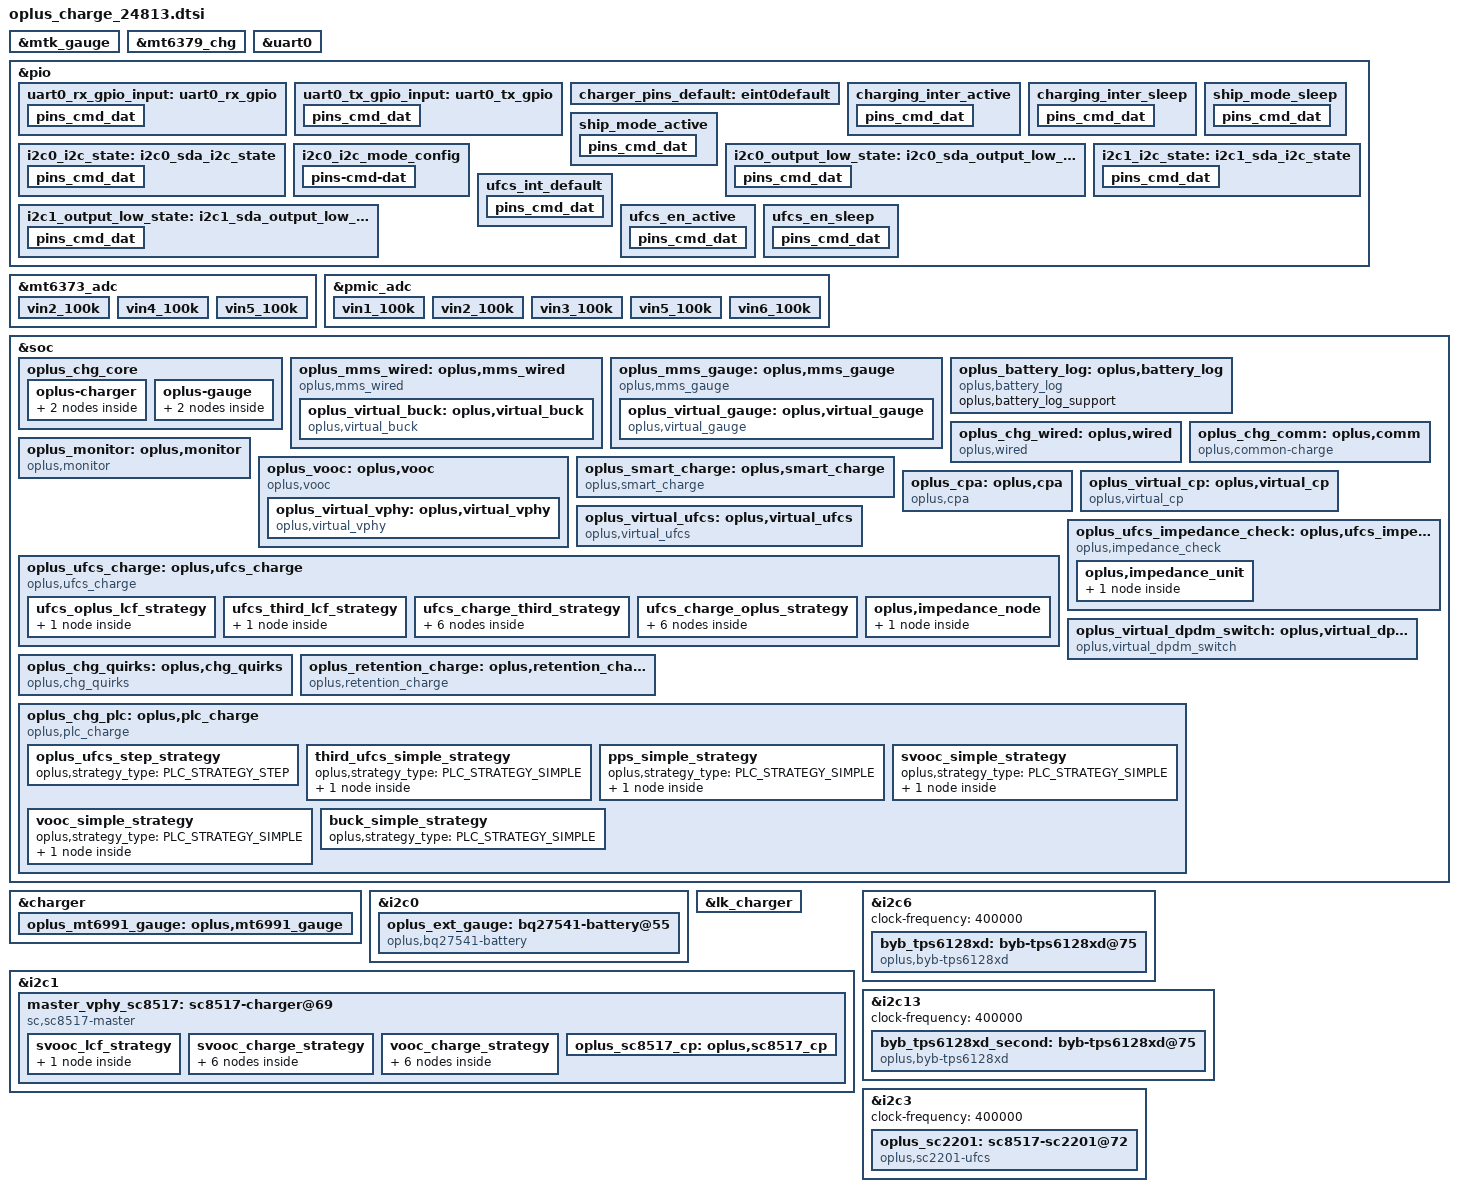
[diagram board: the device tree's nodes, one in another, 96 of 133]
// SPDX-License-Identifier: GPL-2.0-only
/*
* Copyright (C) 2024 Oplus. All rights reserved.
*/
#include <dt-bindings/iio/mt635x-auxadc.h>
#include <dt-bindings/pinctrl/mt6991-pinfunc.h>
#include <dt-bindings/pinctrl/mt65xx.h>
#include "oplus_chg.h"

/* charge start */
&mtk_gauge {
	disable-mtkbattery = <(1)>;
	charger = <&mt6379_chg>;
};

&mt6379_chg {
	chg-tmr = <15>;
};

&uart0 {
	pinctrl-names = "uart0_rx_gpio", "uart0_tx_gpio";
	pinctrl-0 = <&uart0_rx_gpio_input>;
	pinctrl-1 = <&uart0_tx_gpio_input>;
	status = "okay";

	txpin = <160>;
	rxpin = <161>;
};

&pio {
	uart0_rx_gpio_input: uart0_rx_gpio {
		pins_cmd_dat {
			pinmux = <PINMUX_GPIO161__FUNC_GPIO161>;
			input-enable;
			bias-disable;
		};
	};

	uart0_tx_gpio_input: uart0_tx_gpio {
		pins_cmd_dat {
			pinmux = <PINMUX_GPIO160__FUNC_GPIO160>;
			input-enable;
			bias-disable;
		};
	};
};

/* mt6373_adc is defined in mt6373.dtsi */
&mt6373_adc {
	vin2_100k {
		channel = <AUXADC_VIN2>;
		pures = <ADC_PURES_100K>;
	};
	vin4_100k {
		channel = <AUXADC_VIN4>;
		pures = <ADC_PURES_100K>;
	};
	vin5_100k {
		channel = <AUXADC_VIN5>;
		pures = <ADC_PURES_100K>;
	};
};

/* pmic_adc is defined in mt6363.dtsi */
&pmic_adc {
	vin1_100k {
		channel = <AUXADC_VIN1>;
		pures = <ADC_PURES_100K>;
	};
	vin2_100k {
		channel = <AUXADC_VIN2>;
		pures = <ADC_PURES_100K>;
	};
	vin3_100k {
		channel = <AUXADC_VIN3>;
		pures = <ADC_PURES_100K>;
	};
	vin5_100k {
		channel = <AUXADC_VIN5>;
		pures = <ADC_PURES_100K>;
	};
	vin6_100k {
		channel = <AUXADC_VIN6>;
		pures = <ADC_PURES_100K>;
	};
};

&pio {
	charger_pins_default: eint0default {
	};

	charging_inter_active: charging_inter_active {
		pins_cmd_dat {
			pinmux = <PINMUX_GPIO216__FUNC_GPIO216>;
			input-enable;
			bias-pull-up;
		};
	};

	charging_inter_sleep: charging_inter_sleep {
		pins_cmd_dat {
			pinmux = <PINMUX_GPIO216__FUNC_GPIO216>;
			input-enable;
			bias-pull-up;
		};
	};

	ship_mode_sleep: ship_mode_sleep {
		pins_cmd_dat {
			pinmux = <PINMUX_GPIO93__FUNC_GPIO93>;
			output-low;
		};
	};

	ship_mode_active: ship_mode_active {
		pins_cmd_dat {
			pinmux = <PINMUX_GPIO93__FUNC_GPIO93>;
			output-high;
		};
	};
};

&soc {
	oplus_chg_core {
		oplus,chg_framework_v2;
		oplus,smart_charging_screenoff;
		oplus,chg_spec_version = <OPLUS_CHG_SPEC_VER_V3P7>;

		oplus-charger {
			mtk_6991_groups: oplus,mtk_6991-groups {
				functions = <
					OPLUS_IC_FUNC_INIT
					OPLUS_IC_FUNC_EXIT
					OPLUS_IC_FUNC_REG_DUMP
					OPLUS_IC_FUNC_SMT_TEST
					OPLUS_IC_FUNC_BUCK_INPUT_PRESENT
					OPLUS_IC_FUNC_BUCK_INPUT_SUSPEND
					OPLUS_IC_FUNC_BUCK_INPUT_IS_SUSPEND
					OPLUS_IC_FUNC_BUCK_OUTPUT_SUSPEND
					OPLUS_IC_FUNC_BUCK_OUTPUT_IS_SUSPEND
					OPLUS_IC_FUNC_BUCK_SET_ICL
					OPLUS_IC_FUNC_BUCK_GET_ICL
					OPLUS_IC_FUNC_BUCK_SET_FCC
					OPLUS_IC_FUNC_BUCK_SET_FV
					OPLUS_IC_FUNC_BUCK_SET_ITERM
					OPLUS_IC_FUNC_BUCK_GET_INPUT_CURR
					OPLUS_IC_FUNC_BUCK_GET_INPUT_VOL
					OPLUS_IC_FUNC_OTG_BOOST_ENABLE
					OPLUS_IC_FUNC_BUCK_GET_CC_ORIENTATION
					OPLUS_IC_FUNC_BUCK_GET_CHARGER_TYPE
					OPLUS_IC_FUNC_BUCK_RERUN_BC12
					OPLUS_IC_FUNC_BUCK_QC_DETECT_ENABLE
					OPLUS_IC_FUNC_BUCK_SET_QC_CONFIG
					OPLUS_IC_FUNC_BUCK_SET_PD_CONFIG
					OPLUS_IC_FUNC_GET_SHUTDOWN_SOC
					OPLUS_IC_FUNC_BACKUP_SOC
					OPLUS_IC_FUNC_GET_TYPEC_MODE
					OPLUS_IC_FUNC_SET_TYPEC_MODE
					OPLUS_IC_FUNC_GET_TYPEC_ROLE
					OPLUS_IC_FUNC_GET_OTG_ENABLE
					OPLUS_IC_FUNC_BUCK_GET_HW_DETECT
					OPLUS_IC_FUNC_SET_USB_DISCHG_ENABLE
					OPLUS_IC_FUNC_GET_USB_DISCHG_STATUS
					OPLUS_IC_FUNC_IS_OPLUS_SVID
					OPLUS_IC_FUNC_BUCK_GET_USB_BTB_TEMP
					OPLUS_IC_FUNC_BUCK_GET_BATT_BTB_TEMP
					OPLUS_IC_FUNC_BUCK_SET_AICL_POINT
					OPLUS_IC_FUNC_SET_OTG_BOOST_CURR_LIMIT
					OPLUS_IC_FUNC_SET_OTG_BOOST_VOL
					OPLUS_IC_FUNC_BUCK_GET_FV
					OPLUS_IC_FUNC_BUCK_GET_TYPEC_STATE
					OPLUS_IC_FUNC_BUCK_DIS_INSERT_DETECT
					OPLUS_IC_FUNC_BUCK_GET_USB_AICL_ENHANCE
				>;
				virqs = <
					OPLUS_IC_VIRQ_ERR
					OPLUS_IC_VIRQ_CC_DETECT
					OPLUS_IC_VIRQ_PLUGIN
					OPLUS_IC_VIRQ_CC_CHANGED
					OPLUS_IC_VIRQ_CHG_TYPE_CHANGE
					OPLUS_IC_VIRQ_OTG_ENABLE
					OPLUS_IC_VIRQ_SVID
					OPLUS_IC_VIRQ_TYPEC_STATE
				>;
			};
			byb_tps6128xd_groups: oplus,byb-tps6128xd-groups {
				functions = <
					OPLUS_IC_FUNC_INIT
					OPLUS_IC_FUNC_EXIT
					OPLUS_IC_FUNC_REG_DUMP
				>;
				virqs = <
					OPLUS_IC_VIRQ_ERR
				>;
			};
		};

		oplus-gauge {
			bq27541_groups: oplus,bq27541_groups {
				functions = <
					OPLUS_IC_FUNC_INIT
					OPLUS_IC_FUNC_EXIT
					OPLUS_IC_FUNC_REG_DUMP
					OPLUS_IC_FUNC_SMT_TEST
					OPLUS_IC_FUNC_GAUGE_GET_BATT_VOL
					OPLUS_IC_FUNC_GAUGE_GET_BATT_MAX
					OPLUS_IC_FUNC_GAUGE_GET_BATT_MIN
					OPLUS_IC_FUNC_GAUGE_GET_BATT_CURR
					OPLUS_IC_FUNC_GAUGE_GET_BATT_TEMP
					OPLUS_IC_FUNC_GAUGE_GET_BATT_SOC
					OPLUS_IC_FUNC_GAUGE_GET_BATT_FCC
					OPLUS_IC_FUNC_GAUGE_GET_BATT_CC
					OPLUS_IC_FUNC_GAUGE_GET_BATT_RM
					OPLUS_IC_FUNC_GAUGE_GET_BATT_SOH
					OPLUS_IC_FUNC_GAUGE_GET_BATT_AUTH
					OPLUS_IC_FUNC_GAUGE_GET_BATT_HMAC
					OPLUS_IC_FUNC_GAUGE_SET_BATT_FULL
					OPLUS_IC_FUNC_GAUGE_UPDATE_DOD0
					OPLUS_IC_FUNC_GAUGE_UPDATE_SOC_SMOOTH
					OPLUS_IC_FUNC_GAUGE_GET_CB_STATUS
					OPLUS_IC_FUNC_GAUGE_GET_BATT_NUM
					OPLUS_IC_FUNC_GAUGE_GET_DEVICE_TYPE
					OPLUS_IC_FUNC_GAUGE_GET_DEVICE_TYPE_FOR_VOOC
					OPLUS_IC_FUNC_GAUGE_GET_BATT_FCC
					OPLUS_IC_FUNC_GAUGE_GET_BATT_FC
					OPLUS_IC_FUNC_GAUGE_GET_BATT_QM
					OPLUS_IC_FUNC_GAUGE_GET_BATT_PD
					OPLUS_IC_FUNC_GAUGE_GET_BATT_RCU
					OPLUS_IC_FUNC_GAUGE_GET_BATT_RCF
					OPLUS_IC_FUNC_GAUGE_GET_BATT_FCU
					OPLUS_IC_FUNC_GAUGE_GET_BATT_FCF
					OPLUS_IC_FUNC_GAUGE_GET_BATT_SOU
					OPLUS_IC_FUNC_GAUGE_GET_BATT_DO0
					OPLUS_IC_FUNC_GAUGE_GET_BATT_DOE
					OPLUS_IC_FUNC_GAUGE_GET_BATT_TRM
					OPLUS_IC_FUNC_GAUGE_GET_BATT_PC
					OPLUS_IC_FUNC_GAUGE_GET_BATT_QS
					OPLUS_IC_FUNC_GAUGE_IS_SUSPEND
					OPLUS_IC_FUNC_GAUGE_GET_BCC_PARMS
					OPLUS_IC_FUNC_GAUGE_FASTCHG_UPDATE_BCC_PARMS
					OPLUS_IC_FUNC_GAUGE_GET_PREV_BCC_PARMS
					OPLUS_IC_FUNC_GAUGE_SET_BCC_PARMS
					OPLUS_IC_FUNC_GAUGE_SET_PROTECT_CHECK
					OPLUS_IC_FUNC_GAUGE_GET_AFI_UPDATE_DONE
					OPLUS_IC_FUNC_GAUGE_CHECK_RESET
					OPLUS_IC_FUNC_GAUGE_SET_RESET
					OPLUS_IC_FUNC_GAUGE_GET_DEVICE_TYPE_FOR_BCC
					OPLUS_IC_FUNC_GAUGE_GET_DOD0
					OPLUS_IC_FUNC_GAUGE_GET_DOD0_PASSED_Q
					OPLUS_IC_FUNC_GAUGE_GET_QMAX
					OPLUS_IC_FUNC_GAUGE_GET_QMAX_PASSED_Q
					OPLUS_IC_FUNC_GAUGE_GET_REG_INFO
					OPLUS_IC_FUNC_GAUGE_GET_CALIB_TIME
					OPLUS_IC_FUNC_GAUGE_GET_DEEP_DISCHG_COUNT
					OPLUS_IC_FUNC_GAUGE_SET_DEEP_DISCHG_COUNT
					OPLUS_IC_FUNC_GAUGE_GET_DEEP_TERM_VOLT
					OPLUS_IC_FUNC_GAUGE_SET_DEEP_TERM_VOLT
					OPLUS_IC_FUNC_GAUGE_SET_SILI_SPARE_POWER
					OPLUS_IC_FUNC_GAUGE_GET_SILI_SIMULATE_TERM_VOLT
					OPLUS_IC_FUNC_GAUGE_GET_SILI_IC_ALG_TERM_VOLT
					OPLUS_IC_FUNC_GAUGE_SET_SILI_IC_ALG_CFG
					OPLUS_IC_FUNC_GAUGE_GET_SILI_IC_ALG_DSG_ENABLE
					OPLUS_IC_FUNC_GAUGE_SET_SILI_IC_ALG_TERM_VOLT
					OPLUS_IC_FUNC_GAUGE_GET_SILI_ALG_APPLICATION_INFO
					OPLUS_IC_FUNC_GAUGE_GET_SILI_LIFETIME_STATUS
					OPLUS_IC_FUNC_GAUGE_GET_SILI_LIFETIME_INFO
					OPLUS_IC_FUNC_GAUGE_SET_CALIB_TIME
					OPLUS_IC_FUNC_GAUGE_SET_LAST_CC
					OPLUS_IC_FUNC_GAUGE_GET_LAST_CC
					OPLUS_IC_FUNC_GAUGE_GET_DEC_FG_TYPE
					OPLUS_IC_FUNC_GAUGE_GET_DEC_CV_SOH
					OPLUS_IC_FUNC_GAUGE_SET_VCT
					OPLUS_IC_FUNC_GAUGE_GET_VCT
					OPLUS_IC_FUNC_GAUGE_GET_GAUGE_R_INFO
				>;
				virqs = <
					OPLUS_IC_VIRQ_ERR
					OPLUS_IC_VIRQ_OFFLINE
					OPLUS_IC_VIRQ_RESUME
				>;
			};

			mt6991_gauge_groups: oplus,mt6991_gauge_groups {
				functions = <
					OPLUS_IC_FUNC_INIT
					OPLUS_IC_FUNC_EXIT
					OPLUS_IC_FUNC_GAUGE_GET_SUBBOARD_TEMP
				>;
				virqs = <
					OPLUS_IC_VIRQ_ERR
				>;
			};
		};
	};
};

&charger {
	io-channels = <&mt6373_adc AUXADC_VIN2>,
			<&pmic_adc (ADC_PURES_100K_MASK | AUXADC_VIN1)>,
			<&pmic_adc (ADC_PURES_100K_MASK | AUXADC_VIN2)>,
			<&pmic_adc (ADC_PURES_100K_MASK | AUXADC_VIN6)>;
	io-channel-names = "auxadc5-chargeric_temp",
			   "auxadc1-ntc_sub_bat_tem",
			   "auxadc5_batt_btb_temp", "auxadc6_usb_btb_temp";

	pinctrl-names = "default";
	pinctrl-0 = <&charger_pins_default>;
	oplus,support_ntc_01c_precision;
	oplus,support_subboard_ntc;
	max_charger_voltage = <15000000>;
	oplus,usb_aicl_enhance;

	/* ntc_resistance:100k internal_pull_up:100k voltage:1.84v */
	oplus,ntc_temp_volt_1840mv;

	oplus,ic_type = <OPLUS_CHG_IC_BUCK>;
	oplus,ic_index = <0>;

	oplus_mt6991_gauge: oplus,mt6991_gauge {
		oplus,ic_type = <OPLUS_CHG_IC_GAUGE>;
		oplus,ic_index = <1>;
	};
};

&i2c0 {
	status = "okay";
	clock-frequency = <100000>;

	oplus_ext_gauge: bq27541-battery@55 {
		status = "okay";
		compatible = "oplus,bq27541-battery";
		reg = <0x55 0>;
		qcom,modify-soc-smooth;
		qcom,modify-soc-calibration;
		qcom,batt_bq28z610; /* TODO: maybe need update.*/
		qcom,sha1_key_index = <1>;
		oplus,batt_num = <2>;
		oplus,ic_type = <OPLUS_CHG_IC_GAUGE>;
		oplus,ic_index = <0>;

		oplus,bq28z610_afi_buf = /bits/ 8 <
			/* checksum data_len data+ */
			0x24 0x03 0x90 0x45 0x06 /* MIN_RES_POINTS 6 */
			0x24 0x03 0x91 0x45 0x05 /* RA_MAX_DELTA 5 */
			0xd8 0x03 0xe8 0x45 0xfa /* SOH_LOAD_RATE 250 */
			0x2 0x04 0x94 0x45 0x25 0xff /* RES_PARA_FILTER 65317 */
			0x3d 0x04 0x96 0x45 0xed 0xfa /* RA_PARA_FILTER 64237 */
			0xeb 0x03 0x89 0x45 0x46 /* MIN_DOD_RES 70 */
			0x73 0x04 0x8e 0x45 0xb6 0x3 /* RA_PARA_FILTER 950 */
			>;
	};
};

&mt6379_chg {
	support_icl_optimization;
};

&lk_charger {
	charger_by_bidirection;
	support_icl_optimization;
	support_chg_time_cnt;
	is_support_mt6379;
	support_external_gauge_bq28z610;
	external_gauge_type = <EXTERNAL_GAUGE_TYPE_BQ28Z719>;
	support_tuv_authentication;
	support_sdp_screenoff;
	use_extern_gauge;
	support_quickboot_charge;
	sub_board_temp_support;
	sub_board_adc_channel = <18>; /* AUXADC_VIN1 */
	sub_board_adc_pull_up_voltage = <1840>;
	over_high_temp_thr = <60>;
	support_battery_type = <7>;

	/* mt6991 start */
	led-brightness = <102>;
	/* mt6991, such as max_charger_voltage to max-charger-voltage */
	gauge-i2c-id = <0x00>;
	max-charger-voltage = <15000000>;
	boot-battery-voltage = <3350000>;
	usb-charger-current = <500000>;
	ac-charger-current = <2050000>;
	ac-charger-input-current = <1500000>;
	non-std-ac-charger-current = <750000>;
	charging-host-charger-current = <1500000>;
	ta-ac-charger-current = <1500000>;
	pd-charger-current = <500000>;
	/* mt6991 end */
};

&i2c0 {
	pinctrl-names = "i2c-state", "output-low-state", "default";
	pinctrl-0 = <&i2c0_i2c_state>;
	pinctrl-1 = <&i2c0_output_low_state>;
	pinctrl-2 = <&i2c0_i2c_mode_config>;
};
&pio {
	i2c0_i2c_state: i2c0_sda_i2c_state {
		pins_cmd_dat {
			pinmux = <PINMUX_GPIO99__FUNC_SCL0>,
			<PINMUX_GPIO100__FUNC_SDA0>;
			bias-pull-up = <MTK_PULL_SET_RSEL_001>;
		};
	};
	i2c0_output_low_state: i2c0_sda_output_low_state {
		pins_cmd_dat {
			pinmux = <PINMUX_GPIO99__FUNC_GPIO99>,
			<PINMUX_GPIO100__FUNC_GPIO100>;
			output-low;
		};
	};
	i2c0_i2c_mode_config: i2c0_i2c_mode_config {
		pins-cmd-dat {
			pinmux = <PINMUX_GPIO99__FUNC_SCL0>,
			<PINMUX_GPIO100__FUNC_SDA0>;
			bias-pull-up = <MTK_PULL_SET_RSEL_001>;
			input-enable;
		};
	};
};

&soc {
	oplus_mms_wired: oplus,mms_wired {
		compatible = "oplus,mms_wired";
		oplus,buck_ic = <&oplus_virtual_buck>;
		oplus,voocphy_ic = <&oplus_virtual_vphy>;

		oplus,adc_info_name = "100k_1840mv";
		oplus_spec,usbtemp_batttemp_gap = <12>;
		high-temp-scheme;

		/* support for V2.0 usbtemp protect. */
		oplus,support_usbtemp_protect_v2;
		oplus_spec,usbtemp_batt_temp_low = <50>;
		oplus_spec,usbtemp_batt_temp_high = <50>;
		oplus_spec,usbtemp_batt_temp_over_hot = <60>;
		oplus_spec,usbtemp_ntc_temp_low = <57>;
		oplus_spec,usbtemp_ntc_temp_high = <69>;
		oplus_spec,usbtemp_temp_gap_low_with_batt_temp = <7>;
		oplus_spec,usbtemp_temp_gap_high_with_batt_temp = <12>;
		oplus_spec,usbtemp_temp_gap_with_batt_temp_in_over_hot = <15>;
		oplus_spec,usbtemp_temp_gap_low_without_batt_temp = <12>;
		oplus_spec,usbtemp_temp_gap_high_without_batt_temp = <24>;
		oplus_spec.usbtemp_rise_fast_temp_low = <3>;
		oplus_spec.usbtemp_rise_fast_temp_high = <3>;
		oplus_spec.usbtemp_rise_fast_temp_count_low = <30>;
		oplus_spec.usbtemp_rise_fast_temp_count_high = <20>;
		oplus_spec,usbtemp_cool_down_ntc_low = <54>;
		oplus_spec,usbtemp_cool_down_ntc_high = <65>;
		oplus_spec,usbtemp_cool_down_gap_low = <12>;
		oplus_spec,usbtemp_cool_down_gap_high = <20>;
		oplus_spec,usbtemp_cool_down_recover_ntc_low = <48>;
		oplus_spec,usbtemp_cool_down_recover_ntc_high = <60>;
		oplus_spec,usbtemp_cool_down_recover_gap_low = <6>;
		oplus_spec,usbtemp_cool_down_recover_gap_high = <15>;
		oplus_spec,usbtemp_otg_cc_boot_current_limit = <1300000>;

		oplus_virtual_buck: oplus,virtual_buck {
			compatible = "oplus,virtual_buck";

			/* The parameters of the buck_ic have been moved to a separate DTS file configuration */

			oplus,ic_type = <OPLUS_CHG_IC_VIRTUAL_BUCK>;
			oplus,ic_index = <0>;

			/* SHIP_MODE_ON */
			oplus,ship-gpio = <&pio 93 0x00>;

			pinctrl-names = "ship_active", "ship_sleep";
			pinctrl-0 = <&ship_mode_active>;
			pinctrl-1 = <&ship_mode_sleep>;

			io-channels = <&mt6373_adc AUXADC_VIN4>, <&mt6373_adc AUXADC_VIN5>;
			io-channel-names = "usb_temp_adc_l", "usb_temp_adc_r";

			oplus,uart_tx-gpio = <&pio 160 0x00>;
			oplus,uart_rx-gpio = <&pio 161 0x00>;
		};
	};

	oplus_mms_gauge: oplus,mms_gauge {
		compatible = "oplus,mms_gauge";
		oplus,gauge_ic = <&oplus_virtual_gauge>;
		oplus,topic-update-interval = <10000>;
		oplus,support_subboard_ntc;
		oplus,fcl_support;
		oplus,fcl_index = <0>;
		oplus,vb_offset = <0>;

		/* The parameters of the silicon battery have been moved to a separate DTS file configuration */

		oplus_virtual_gauge: oplus,virtual_gauge {
			compatible = "oplus,virtual_gauge";
			oplus,gauge_ic = <&oplus_ext_gauge &oplus_mt6991_gauge>;
			oplus,gauge_ic_index = <0 1>;
			oplus,gauge_ic_func_group = <&bq27541_groups &mt6991_gauge_groups>;
			oplus,batt_capacity_mah = <6700>;
			oplus,ic_type = <OPLUS_CHG_IC_VIRTUAL_GAUGE>;
			oplus,ic_index = <0>;
		};
	};
};

&soc {
	oplus_battery_log: oplus,battery_log {
		compatible = "oplus,battery_log";

		oplus,battery_log_support;
	};

	oplus_chg_wired: oplus,wired {
		compatible = "oplus,wired";

		oplus,vooc-support;

		oplus_spec,vbatt_pdqc_to_5v_thr = <4500>;
		oplus_spec,vbatt_pdqc_to_9v_thr = <4500>;
		oplus_spec,pd-iclmax-ma = <2000>;
		oplus_spec,qc-iclmax-ma = <2000>;
		oplus_spec,non-standard-ibatmax-ma = <500>;
		oplus_spec,input-power-mw = <
			2500		/* OPLUS_WIRED_CHG_MODE_UNKNOWN */
			2500		/* OPLUS_WIRED_CHG_MODE_SDP */
			7500		/* OPLUS_WIRED_CHG_MODE_CDP */
			10000		/* OPLUS_WIRED_CHG_MODE_DCP */
			15000		/* OPLUS_WIRED_CHG_MODE_VOOC */
			13500		/* OPLUS_WIRED_CHG_MODE_QC */
			13500		/* OPLUS_WIRED_CHG_MODE_PD */
		>;
		oplus_spec,led_on-fccmax-ma = <0 1526 2902 3300 3300 3300 3300 1000 0>;
		oplus_spec,fccmax-ma-lv = <
			0 1526 2200 2200 2200 2200 2200 2200 0	/* OPLUS_WIRED_CHG_MODE_UNKNOWN */
			0 580  600  600  600  600  600  600  0	/* OPLUS_WIRED_CHG_MODE_SDP */
			0 580 1600 1600 1600 1600 1600 1600 0	/* OPLUS_WIRED_CHG_MODE_CDP */
			0 580 2200 2200 2200 2200 2200 2200 0	/* OPLUS_WIRED_CHG_MODE_DCP */
			0 580 2902 3300 3300 3300 3300 3300 0	/* OPLUS_WIRED_CHG_MODE_VOOC */
			0 580 2902 3300 3300 3300 3300 3300 0	/* OPLUS_WIRED_CHG_MODE_QC */
			0 580 2902 3300 3300 3300 3300 3300 0	/* OPLUS_WIRED_CHG_MODE_PD */
		>;
		oplus_spec,fccmax-ma-hv = <
			0 509  1039 2200 2200 2200 2200 2200 0	/* OPLUS_WIRED_CHG_MODE_UNKNOWN */
			0 580  600  600  600  600  600  600 0	/* OPLUS_WIRED_CHG_MODE_SDP */
			0 580  1160 1600 1600 1600 1600 1000 0	/* OPLUS_WIRED_CHG_MODE_CDP */
			0 580  1160 1740 2200 2200 2200 1000 0	/* OPLUS_WIRED_CHG_MODE_DCP */
			0 580  1160 1740 2902 3300 3300 1000 0	/* OPLUS_WIRED_CHG_MODE_VOOC */
			0 580  1160 1740 2902 3300 3300 1000 0	/* OPLUS_WIRED_CHG_MODE_QC */
			0 580  1160 1740 2902 3300 3300 1000 0	/* OPLUS_WIRED_CHG_MODE_PD */
		>;
                oplus_spec,cool_down_sale_pdqc_vol_mv = <9000>;
                oplus_spec,cool_down_sale_pdqc_curr_ma = <1200>;
                oplus_spec,cool_down_pdqc_vol_mv = <5000 5000 5000 9000 9000>;
                oplus_spec,cool_down_pdqc_curr_ma = <1200 1500 2000 1500 2000>;
		oplus_spec,cool_down_vooc_curr_ma = <1200 1500 2000 2500 3000 3000>;
		oplus_spec,cool_down_normal_curr_ma = <1200 1500 2000>;

		oplus_spec,vbus_ov_thr_mv = <11000 11000>;
		oplus_spec,vbus_uv_thr_mv = <4300 4300>;

		/* Temperature control for power off charging. */
		/* first data is strategy used temp type */
		oplus,pd_strategy_name = "cgcl";
		oplus,pd_strategy_data = < OPLUS_STRATEGY_USE_SHELL_TEMP
					   0   410 2000 1 0
					   400 420 1500 2 0
					   410 430 1000 2 1>;

		oplus,qc_strategy_name = "cgcl";
		oplus,qc_strategy_data = < OPLUS_STRATEGY_USE_SHELL_TEMP
					   0   410 2000 1 0
					   400 420 1500 2 0
					   410 430 1200 2 1>;
	};

	oplus_chg_comm: oplus,comm {
		compatible = "oplus,common-charge";
		oplus_spec,dec_step = <20>;
		oplus_spec,dec-vol-cc-full-thr = <0 400 600 800 1000 1200>;
		oplus_spec,dec-vol-fv-full-mv = <0 20 20 40 40 40>;
		oplus_spec,dec-vol-vct-mv = <100 120 120 140 140 140>;
		oplus_spec,batt-them-thr = <(-100) 0 50 120 160 350 450 530>;
		oplus_spec,iterm-ma = <171>;
		oplus_spec,removed_bat_decidegc = <390>; /*-39 degree*/
		oplus_spec,fv-mv = <4500 4500 4500 4500 4500 4500 4475 4130 4130>;
		oplus_spec,sw-fv-mv = <4450 4450 4450 4450 4450 4450 4425 4080 4080>;
		oplus_spec,hw-fv-inc-mv = <0 18 18 18 18 18 18 18 0>;
		oplus_spec,sw-over-fv-mv = <4510 4510 4510 4510 4510 4510 4485 4140 4140>;
		oplus_spec,sw-over-fv-dec-mv = <8>;
		oplus_spec,non-standard-sw-fv-mv = <3930>;
		oplus_spec,non-standard-fv-mv = <3980>;
		oplus_spec,non-standard-hw-fv-inc-mv = <18>;
		oplus_spec,non-standard-sw-over-fv-mv = <3990>;
		oplus_spec,non-standard-vbatdet-mv = <3680>;
		oplus_spec,wired-vbatdet-mv = <0 4200 4300 4400 4400 4400 4375 4030 0>;
		oplus_spec,fcc-gear-thr-mv = <4180>;
		oplus_spec,fcc-gear-shake-mv = <550 550 350 200 200 150 150 100 100>;
		oplus_spec,vbatt-ov-thr-mv = <4600>;

		oplus_spec,full_pre_ffc_judge;
		oplus_spec,full-pre-ffc-mv = <4530>;
		oplus_spec,ffc-temp-thr = <120 210 350 440>;
		oplus_spec,wired-ffc-step-max = <2>;
		oplus_spec,wired-ffc-fv-mv = <4630 4630>;
		oplus_spec,wired-ffc-fv-cutoff-mv = <4550 4525 4490
						     4520 4505 4475>;
		oplus_spec,wired-ffc-fcc-ma = <1100 1100 1100
					       700 700 700>;
		oplus_spec,wired-ffc-fcc-cutoff-ma = <400 400 400
						      200 200 200>;
		oplus_spec,drop_soc_2_temp_ladder = <(-50) 0 0 0 0 0 0 0 0 0>;
		oplus_spec,volt_diff_ladder_of_drop_soc_2 = <20 50 0 0 0 0 0 0 0 0>;
		oplus_spec,keep_soc_2_temp_ladder = <(-200) (-50) 0 0 0 0 0 0 0 0>;
		oplus_spec,volt_diff_ladder_of_keep_soc_2 = <10 20 30 0 0 0 0 0 0 0>;
		oplus_spec,back_rm_of_drop_soc_2 = <67>;
		oplus_spec,back_rm_of_drop_soc_1 = <67>;
		oplus_spec,load_current_of_drop_soc_2 = <1500>;
		oplus_spec,load_current_of_drop_soc_1 = <2000>;
		oplus_spec,current_limit_of_drop_soc_2 = <350>;
		oplus_spec,volt_of_fast_drop_soc_1 = <2900>;
		oplus_spec,support_uisoc_low_battery_control;
		oplus_spec,support_gauge_r_track;

		oplus_spec,vbat_uv_thr_mv = <3000>;
		oplus_spec,vbat_charging_uv_thr_mv = <3000>;
		oplus_spec,vbat_charging_uv_delata_mv = <0>;

		/*If use subboard NTC as battery temp, config it as 20, otherwise 0 */
		oplus_spec,tbatt_power_off_cali_temp = <0>;
		oplus_spec,poweroff_high_batt_temp = <720>;
		oplus_spec,poweroff_emergency_batt_temp = <770>;
		oplus,vooc_show_ui_soc_decimal;
		oplus,ui_soc_decimal_speedmin = <20>;

		oplus,gauge_stuck_jump_support;
		oplus,gauge_stuck_threshold = <15>;
		oplus,gauge_stuck_time = <50>;

		oplus,smooth_switch;
		oplus,reserve_chg_soc = <2>;
		oplus,reserve_dis_soc = <2>;

		oplus,ui_soc_2_voltage_comp_mv = <30>;
		oplus,chg_shutdown_max_mv = <3000>;

		oplus_spec,batt_full_time = <300>;
	};

	oplus_monitor: oplus,monitor {
		compatible = "oplus,monitor";
		oplus,topic-update-interval = <60000>;

		track,fast_chg_break_t_thd = <1400>;
		track,general_chg_break_t_thd = <300>;
		track,voocphy_type = <TRACK_AP_SINGLE_CP_VOOCPHY>;
		track,wired_max_power = <100000>;
		track,wired_fast_chg_scheme = <0>;

		track,gauge_status_ctrl;
		track,nominal_qmax1 = <3491>;
		track,nominal_fcc1 = <6060>;
		track,external_gauge_num = <1>;

		track,sili_cc_term_vol_curve = <400 3300 800 3400 1200 3500 10000 3600>;
		track,gauge_max_cell_vol = <4600>;
		track,gauge_max_charge_curr = <13000>;
		track,gauge_max_dischg_curr = <6000>;
		track,gauge_min_cell_temp = <30>;
		track,gauge_max_cell_temp = <70>;
		track,gauge_firmware_term_volt = <3050>;
		track,gauge_lifetime_support;

		oplus,chg_into_liquid;
		oplus,chg_into_liquid_cc_disconnect = <10>;
		oplus,chg_into_liquid_total_time = <5000>;
		oplus,chg_into_liquid_max_interval_time = <700>;
	};

	oplus_vooc: oplus,vooc {
		compatible = "oplus,vooc";
		oplus,vooc_ic = <&oplus_virtual_vphy>;

		oplus_spec,vooc_soc_range = <50 75 85>;
		oplus_spec,vooc_temp_range = <50 120 180 350 450>;

		oplus,vooc_data_width = <7>;
		oplus,vooc_curr_max = <CURR_LIMIT_7BIT_9_5A>;
		oplus,support_vooc_by_normal_charger_path;
		oplus,vooc_project = <8>;
		oplus,vooc_curr_table_type = <VOOC_CURR_TABLE_2_0>;
		oplus,vooc_power_max_w = <100>;
		oplus,voocphy_support = <2>;
		oplus,support_fake_vooc_check;

		oplus,smart_chg_bcc_support;
		oplus,subboard_ntc_abnormal_current = <7300>;

		oplus,abnormal_adapter_current = <CURR_LIMIT_7BIT_9_5A CURR_LIMIT_7BIT_9_5A
						CURR_LIMIT_7BIT_5_0A CURR_LIMIT_7BIT_5_0A
						CURR_LIMIT_7BIT_4_0A CURR_LIMIT_7BIT_4_0A
						CURR_LIMIT_7BIT_3_0A CURR_LIMIT_7BIT_3_0A
						CURR_LIMIT_7BIT_2_0A CURR_LIMIT_7BIT_2_0A>;

		oplus,abnormal_over_80w_adapter_current = <CURR_LIMIT_7BIT_9_5A CURR_LIMIT_7BIT_9_5A
						CURR_LIMIT_7BIT_7_0A CURR_LIMIT_7BIT_7_0A
						CURR_LIMIT_7BIT_6_0A CURR_LIMIT_7BIT_6_0A
						CURR_LIMIT_7BIT_5_0A CURR_LIMIT_7BIT_5_0A
						CURR_LIMIT_7BIT_4_0A CURR_LIMIT_7BIT_4_0A
						CURR_LIMIT_7BIT_3_0A CURR_LIMIT_7BIT_3_0A
						CURR_LIMIT_7BIT_2_0A CURR_LIMIT_7BIT_2_0A>;

		/* first data is strategy used temp type */
		oplus,general_strategy_name = "cgcl";
		oplus,general_strategy_data = < OPLUS_STRATEGY_USE_SHELL_TEMP
						0   385 CURR_LIMIT_7BIT_9_5A 1 0
						375 410 CURR_LIMIT_7BIT_7_0A 2 0
						400 420 CURR_LIMIT_7BIT_5_0A 3 1
						410 440 CURR_LIMIT_7BIT_4_0A 4 2
						430 450 CURR_LIMIT_7BIT_2_0A 4 3>;

		oplus,bypass_strategy_name = "cgcl";
		oplus,bypass_strategy_data = < OPLUS_STRATEGY_USE_SHELL_TEMP
					       0   380 CP_CURR_LIMIT_7BIT_4_0A  1 0
					       370 400 CP_CURR_LIMIT_7BIT_3_0A  2 0
					       390 420 CP_CURR_LIMIT_7BIT_2_4A  2 1>;

		oplus,plc_strategy-data = <&buck_simple_strategy &svooc_simple_strategy &vooc_simple_strategy>;
		oplus,plc_strategy-names = "default", "svooc", "vooc";

		oplus_virtual_vphy: oplus,virtual_vphy {
			compatible = "oplus,virtual_vphy";
			oplus,vphy_ic = <&master_vphy_sc8517>;
			oplus,dpdm_switch_ic = <&oplus_virtual_dpdm_switch>;
			oplus,ic_type = <OPLUS_CHG_IC_VIRTUAL_VPHY>;
			oplus,ic_index = <0>;
		};
	};
	oplus_smart_charge: oplus,smart_charge {
		compatible = "oplus,smart_charge";
		oplus,smart_chg_soh_support;
		oplus,quick_mode_gain_support;
	};

	oplus_cpa: oplus,cpa {
		compatible = "oplus,cpa";
		oplus,protocol_list = <CHG_PROTOCOL_UFCS 100
				       CHG_PROTOCOL_VOOC 100
				       CHG_PROTOCOL_PD 18
				       CHG_PROTOCOL_QC 18>;
		oplus,default_protocol_list = <CHG_PROTOCOL_UFCS
					       CHG_PROTOCOL_VOOC
					       CHG_PROTOCOL_PD>;
		oplus,protocol_wait_list = <CHG_PROTOCOL_UFCS 1000>;
	};

	oplus_virtual_cp: oplus,virtual_cp {
		compatible = "oplus,virtual_cp";

		oplus,ic_type = <OPLUS_CHG_IC_VIRTUAL_CP>;
		oplus,ic_index = <0>;

		oplus,cp_ic = <&oplus_sc8517_cp>;
		oplus,input_curr_max_ma = <9100>;

		oplus,cp_ic_connect = <OPLUS_CHG_IC_CONNECT_PARALLEL>;
		oplus,main_cp = <0>;

		oplus,reg_proc_node;
	};

	oplus_virtual_ufcs: oplus,virtual_ufcs {
		compatible = "oplus,virtual_ufcs";

		oplus,ic_type = <OPLUS_CHG_IC_VIRTUAL_UFCS>;
		oplus,ic_index = <0>;
	};

	oplus_ufcs_charge: oplus,ufcs_charge {
		compatible = "oplus,ufcs_charge";
		oplus,ufcs_ic = <&oplus_virtual_ufcs>;
		oplus,cp_ic = <&oplus_virtual_cp>;
		oplus,dpdm_switch_ic = <&oplus_virtual_dpdm_switch>;

		oplus,ufcs_boot_time_retry = <12>;
		oplus,impedance_unit = <&oplus_ufcs_impedance_unit>;
		oplus,ufcs_need_reset_adapter;

		oplus,target_vbus_mv = <11000>;
		oplus,curr_max_ma = <9100>;
		oplus,subboard_ntc_abnormal_current = <7300>;
		oplus,ufcs_warm_allow_vol = <4000>;
		oplus,ufcs_warm_allow_soc = <55>;
		oplus,ufcs_strategy_normal_current = <9100>;
		oplus,ufcs_over_high_or_low_current = <9100>;
		oplus,ufcs_timeout_third = <16585>;
		oplus,ufcs_timeout_oplus = <16585>;
		oplus,ufcs_ibat_over_third = <5400>;
		oplus,ufcs_ibat_over_oplus = <10500>;
		oplus,ufcs_ibus_over_oplus = <11000>;
		oplus,ufcs_full_cool_sw_vbat = <4600>;
		oplus,ufcs_full_normal_sw_vbat = <4600>;
		oplus,ufcs_full_normal_hw_vbat = <4610>;
		oplus,ufcs_full_ffc_vbat = <4540>;
		oplus,ufcs_full_warm_vbat = <4130>;
		oplus,ufcs_full_cool_sw_vbat_third = <4500>;
		oplus,ufcs_full_normal_sw_vbat_third= <4500>;
		oplus,ufcs_full_normal_hw_vbat_third = <4540>;
		oplus,ufcs_current_change_timeout = <100>;
		oplus,ufcs_strategy_batt_high_temp = <400 420 430 390 410 420>;
		oplus,ufcs_strategy_high_current = <6000 5000 3000 9100 6000 5000>;
		oplus,ufcs_little_cool_high_temp = <210>;
		oplus,curve_strategy_name = "pps_ufcs_curve_v2";
		oplus_spec,ufcs_high_soc = <90>;
		oplus_spec,ufcs_low_soc = <0>;
		oplus_spec,ufcs_high_temp = <510>;
		oplus_spec,ufcs_low_temp = <50>;
		oplus_spec,ufcs_high_soc_third = <85>;
		oplus,ufcs_charge_strategy_temp = <0 50 120 160 350 440 510>;

		oplus,plc_strategy-data = <&oplus_ufcs_step_strategy &third_ufcs_simple_strategy>;
		oplus,plc_strategy-names = "default", "third";

		/* Temperature control for power off charging */
		oplus,temperature_strategy_name = "cgcl";
		oplus,temperature_strategy_data = < OPLUS_STRATEGY_USE_SHELL_TEMP
						    0   385 9100 1 0
						    375 410 7000 2 0
						    400 420 5000 3 1
						    410 440 4000 4 2
						    430 450 2000 4 3>;


		ufcs_oplus_lcf_strategy {
			oplus,temp_type = <OPLUS_STRATEGY_USE_SHELL_TEMP>;
			oplus,temp_range = <0 50 120 160 210 380 440>;

			strategy_temp_range_curves {
				strategy_temp_range_t0 =	<460 4570 0
								 435 4560 0
								 410 4550 0
								 385 4540 0
								 360 4530 1>;
				strategy_temp_range_t1 =	<500 4570 0
								 465 4565 0
								 430 4550 0
								 395 4540 0
								 360 4530 1>;
				strategy_temp_range_t2 =	<600 4570 0
								 555 4565 0
								 510 4550 0
								 465 4540 0
								 420 4530 1>;
				strategy_temp_range_t3 =	<750 4570 0
								 700 4565 0
								 600 4550 0
								 500 4540 0
								 350 4530 1>;
				strategy_temp_range_t4 =	<1250 4570 0
								 1200 4565 0
								 1100 4550 0
								 1000 4540 0
								 850 4530 1>;
				strategy_temp_range_t5 =	<2150 4570 0
								 2100 4565 0
								 2000 4550 0
								 1900 4540 0
								 1750 4530 1>;
			};
		};

		ufcs_third_lcf_strategy {
			oplus,temp_type = <OPLUS_STRATEGY_USE_SHELL_TEMP>;
			oplus,temp_range = <0 50 120 160 210 380 440>;

			strategy_temp_range_curves {
				strategy_temp_range_t0 =	<460 4570 0
								 435 4560 0
								 410 4550 0
								 385 4540 0
								 360 4530 1>;
				strategy_temp_range_t1 =	<550 4570 0
								 515 4565 0
								 480 4550 0
								 445 4540 0
								 410 4530 1>;
				strategy_temp_range_t2 =	<700 4570 0
								 655 4565 0
								 610 4550 0
								 565 4540 0
								 520 4530 1>;
				strategy_temp_range_t3 =	<800 4570 0
								 750 4565 0
								 650 4550 0
								 550 4540 0
								 400 4530 1>;
				strategy_temp_range_t4 =	<1300 4570 0
								 1250 4565 0
								 1150 4550 0
								 1050 4540 0
								 900 4530 1>;
				strategy_temp_range_t5 =	<2200 4570 0
								 2150 4565 0
								 2050 4550 0
								 1950 4540 0
								 1800 4530 1>;
			};
		};

		ufcs_charge_third_strategy {
			oplus,temp_type = <OPLUS_STRATEGY_USE_SHELL_TEMP>;
			oplus,soc_range = <0 20 35 55 75 85 90>;
			oplus,temp_range = <0 50 120 160 210 350 440 510>;

			strategy_soc_range_min {
				strategy_temp_little_cold =	<11000 4140 1300 0 0
								11000 4150 1000 1 0>;
				strategy_temp_cool =		<11000 4150 2400 0 0
								11000 4150 2000 0 0
								11000 4320 1500 0 0
								11000 4330 1000 1 0>;
				strategy_temp_little_cool =	<11000 4150 3000 0 0
								11000 4150 2500 0 0
								11000 4330 2400 0 0
								11000 4330 2000 0 0
								11000 4490 1500 0 0
								11000 4500 1000 1 0>;
				strategy_temp_little_cool_high = <11000 4280 4000 0 0
								11000 4490 3600 0 0
								11000 4490 3500 0 0
								11000 4490 3000 0 0
								11000 4490 2500 0 0
								11000 4490 2000 0 0
								11000 4490 1500 0 0
								11000 4500 1000 1 0>;
				strategy_temp_normal_low =	<11000 4490 4000 0 0
								11000 4490 3500 0 0
								11000 4490 3000 0 0
								11000 4490 2500 0 0
								11000 4490 2000 0 0
								11000 4490 1500 0 0
								11000 4500 1000 1 0>;
				strategy_temp_normal_high =	<11000 4465 4000 0 0
								11000 4465 3500 0 0
								11000 4465 3000 0 0
								11000 4465 2500 0 0
								11000 4465 2000 0 0
								11000 4465 1500 0 0
								11000 4475 1000 1 0>;
				strategy_temp_warm =		<11000 4120 1700 0 0
								11000 4120 1500 0 0
								11000 4130 1000 1 0>;
			};
			strategy_soc_range_low {
				strategy_temp_little_cold =	<11000 4140 1300 0 0
								11000 4150 1000 1 0>;
				strategy_temp_cool =		<11000 4150 2400 0 0
								11000 4150 2000 0 0
								11000 4320 1500 0 0
								11000 4330 1000 1 0>;
				strategy_temp_little_cool =	<11000 4150 3000 0 0
								11000 4150 2500 0 0
								11000 4330 2400 0 0
								11000 4330 2000 0 0
								11000 4490 1500 0 0
								11000 4500 1000 1 0>;
				strategy_temp_little_cool_high = <11000 4280 4000 0 0
								11000 4490 3600 0 0
								11000 4490 3500 0 0
								11000 4490 3000 0 0
								11000 4490 2500 0 0
								11000 4490 2000 0 0
								11000 4490 1500 0 0
								11000 4500 1000 1 0>;
				strategy_temp_normal_low =	<11000 4490 4000 0 0
								11000 4490 3500 0 0
								11000 4490 3000 0 0
								11000 4490 2500 0 0
								11000 4490 2000 0 0
								11000 4490 1500 0 0
								11000 4500 1000 1 0>;
				strategy_temp_normal_high =	<11000 4465 4000 0 0
								11000 4465 3500 0 0
								11000 4465 3000 0 0
								11000 4465 2500 0 0
								11000 4465 2000 0 0
								11000 4465 1500 0 0
								11000 4475 1000 1 0>;
				strategy_temp_warm =		<11000 4120 1700 0 0
								11000 4120 1500 0 0
								11000 4130 1000 1 0>;
			};
			strategy_soc_range_mid_low {
				strategy_temp_little_cold =	<11000 4140 1300 0 0
								11000 4150 1000 1 0>;
				strategy_temp_cool =		<11000 4150 2400 0 0
								11000 4150 2000 0 0
								11000 4320 1500 0 0
								11000 4330 1000 1 0>;
				strategy_temp_little_cool =	<11000 4150 3000 0 0
								11000 4150 2500 0 0
								11000 4330 2400 0 0
								11000 4330 2000 0 0
								11000 4490 1500 0 0
								11000 4500 1000 1 0>;
				strategy_temp_little_cool_high = <11000 4280 4000 0 0
								11000 4490 3600 0 0
								11000 4490 3500 0 0
								11000 4490 3000 0 0
								11000 4490 2500 0 0
								11000 4490 2000 0 0
								11000 4490 1500 0 0
								11000 4500 1000 1 0>;
				strategy_temp_normal_low =	<11000 4490 4000 0 0
								11000 4490 3500 0 0
								11000 4490 3000 0 0
								11000 4490 2500 0 0
								11000 4490 2000 0 0
								11000 4490 1500 0 0
								11000 4500 1000 1 0>;
				strategy_temp_normal_high =	<11000 4465 4000 0 0
								11000 4465 3500 0 0
								11000 4465 3000 0 0
								11000 4465 2500 0 0
								11000 4465 2000 0 0
								11000 4465 1500 0 0
								11000 4475 1000 1 0>;
				strategy_temp_warm =		<11000 4120 1500 0 0
								11000 4130 1000 1 0>;
			};
			strategy_soc_range_mid {
				strategy_temp_little_cold =	<11000 4140 1300 0 0
								11000 4150 1000 1 0>;
				strategy_temp_cool =		<11000 4150 2000 0 0
								11000 4320 1500 0 0
								11000 4330 1000 1 0>;
				strategy_temp_little_cool =	<11000 4150 3000 0 0
								11000 4150 2500 0 0
								11000 4330 2400 0 0
								11000 4330 2000 0 0
								11000 4490 1500 0 0
								11000 4500 1000 1 0>;
				strategy_temp_little_cool_high = <11000 4490 3000 0 0
								11000 4490 2500 0 0
								11000 4490 2000 0 0
								11000 4490 1500 0 0
								11000 4500 1000 1 0>;
				strategy_temp_normal_low =	<11000 4490 3500 0 0
								11000 4490 3000 0 0
								11000 4490 2500 0 0
								11000 4490 2000 0 0
								11000 4490 1500 0 0
								11000 4500 1000 1 0>;
				strategy_temp_normal_high =	<11000 4465 4000 0 0
								11000 4465 3500 0 0
								11000 4465 3000 0 0
								11000 4465 2500 0 0
								11000 4465 2000 0 0
								11000 4465 1500 0 0
								11000 4475 1000 1 0>;
				strategy_temp_warm =		<11000 4130 1000 1 0>;
			};
			strategy_soc_range_mid_high {
				strategy_temp_little_cold =	<11000 4150 1000 1 0>;
				strategy_temp_cool =		<11000 4320 1500 0 0
								11000 4330 1000 1 0>;
				strategy_temp_little_cool =	<11000 4330 2000 0 0
								11000 4490 1500 0 0
								11000 4500 1000 1 0>;
				strategy_temp_little_cool_high = <11000 4490 2000 0 0
								11000 4490 1500 0 0
								11000 4500 1000 1 0>;
				strategy_temp_normal_low =	<11000 4490 2500 0 0
								11000 4490 2000 0 0
								11000 4490 1500 0 0
								11000 4500 1000 1 0>;
				strategy_temp_normal_high =	<11000 4465 2500 0 0
								11000 4465 2000 0 0
								11000 4465 1500 0 0
								11000 4475 1000 1 0>;
				strategy_temp_warm =		<11000 4130 1000 1 0>;
			};
			strategy_soc_range_high {
				strategy_temp_little_cold =	<11000 4150 1000 1 0>;
				strategy_temp_cool =		<11000 4500 1000 1 0>;
				strategy_temp_little_cool =	<11000 4500 1000 1 0>;
				strategy_temp_little_cool_high = <11000 4500 1000 1 0>;
				strategy_temp_normal_low =	<11000 4500 1000 1 0>;
				strategy_temp_normal_high =	<11000 4475 1000 1 0>;
				strategy_temp_warm =		<11000 4130 1000 1 0>;
			};
		};

		ufcs_charge_oplus_strategy {
			oplus,temp_type = <OPLUS_STRATEGY_USE_SHELL_TEMP>;
			oplus,soc_range = <0 20 35 55 75 85 90>;
			oplus,temp_range = <0 50 120 160 210 350 440 510>;

			strategy_soc_range_min {
				strategy_temp_little_cold =	<11000 4150 2200 0 0
								11000 4570 1160 1 0>;
				strategy_temp_cool =		<11000 4150 2400 0 0
								11000 4150 2000 0 0
								11000 4330 1500 0 0
								11000 4330 1000 0 0
								11000 4560 900 0 0
								11000 4570 500 1 0>;
				strategy_temp_little_cool =	<11000 4150 3000 0 0
								11000 4150 2500 0 0
								11000 4330 2400 0 0
								11000 4330 2000 0 0
								11000 4560 1500 0 0
								11000 4560 1000 0 0
								11000 4570 600 1 0>;
				strategy_temp_little_cool_high = <11000 4150 6100 0 0
								11000 4150 6000 0 0
								11000 4150 5500 0 0
								11000 4150 5000 0 0
								11000 4280 4500 0 0
								11000 4280 4000 0 0
								11000 4520 3600 0 0
								11000 4520 3500 0 0
								11000 4560 3000 0 0
								11000 4560 2500 0 0
								11000 4560 2000 0 0
								11000 4560 1500 0 0
								11000 4560 1000 0 0
								11000 4570 800 1 0>;
				strategy_temp_normal_low =	<11000 4110 9100 0 120
								11000 4110 9000 0 120
								11000 4110 8500 0 180
								11000 4220 8100 0 180
								11000 4220 8000 0 180
								11000 4370 7700 0 180
								11000 4370 7500 0 180
								11000 4370 7000 0 0
								11000 4370 6500 0 0
								11000 4370 6000 0 0
								11000 4470 5900 0 0
								11000 4470 5500 0 0
								11000 4470 5000 0 0
								11000 4470 4500 0 0
								11000 4520 4400 0 0
								11000 4520 4000 0 0
								11000 4560 3500 0 0
								11000 4560 3000 0 0
								11000 4560 2500 0 0
								11000 4560 2000 0 0
								11000 4560 1500 0 0
								11000 4570 1300 1 0>;
				strategy_temp_normal_high =	<11000 4110 9100 0 120
								11000 4110 9000 0 120
								11000 4110 8500 0 180
								11000 4220 8100 0 180
								11000 4220 8000 0 180
								11000 4370 7700 0 180
								11000 4370 7500 0 180
								11000 4370 7000 0 0
								11000 4370 6500 0 0
								11000 4370 6000 0 0
								11000 4470 5900 0 0
								11000 4470 5500 0 0
								11000 4470 5000 0 0
								11000 4470 4500 0 0
								11000 4520 4400 0 0
								11000 4520 4000 0 0
								11000 4560 3500 0 0
								11000 4560 3000 0 0
								11000 4560 2500 0 0
								11000 4570 2200 1 0>;
				strategy_temp_warm =		<11000 4120 1700 0 0
								11000 4120 1500 0 0
								11000 4120 1000 0 0
								11000 4130 500 1 0>;
			};
			strategy_soc_range_low {
				strategy_temp_little_cold =	<11000 4150 2200 0 0
								11000 4570 1160 1 0>;
				strategy_temp_cool =		<11000 4150 2400 0 0
								11000 4150 2000 0 0
								11000 4330 1500 0 0
								11000 4330 1000 0 0
								11000 4560 900 0 0
								11000 4570 500 1 0>;
				strategy_temp_little_cool =	<11000 4150 3000 0 0
								11000 4150 2500 0 0
								11000 4330 2400 0 0
								11000 4330 2000 0 0
								11000 4560 1500 0 0
								11000 4560 1000 0 0
								11000 4570 600 1 0>;
				strategy_temp_little_cool_high = <11000 4150 6100 0 0
								11000 4150 6000 0 0
								11000 4150 5500 0 0
								11000 4150 5000 0 0
								11000 4280 4500 0 0
								11000 4280 4000 0 0
								11000 4520 3600 0 0
								11000 4520 3500 0 0
								11000 4560 3000 0 0
								11000 4560 2500 0 0
								11000 4560 2000 0 0
								11000 4560 1500 0 0
								11000 4560 1000 0 0
								11000 4570 800 1 0>;
				strategy_temp_normal_low =	<11000 4110 9100 0 120
								11000 4110 9000 0 120
								11000 4110 8500 0 180
								11000 4220 8100 0 180
								11000 4220 8000 0 180
								11000 4370 7700 0 180
								11000 4370 7500 0 180
								11000 4370 7000 0 0
								11000 4370 6500 0 0
								11000 4370 6000 0 0
								11000 4470 5900 0 0
								11000 4470 5500 0 0
								11000 4470 5000 0 0
								11000 4470 4500 0 0
								11000 4520 4400 0 0
								11000 4520 4000 0 0
								11000 4560 3500 0 0
								11000 4560 3000 0 0
								11000 4560 2500 0 0
								11000 4560 2000 0 0
								11000 4560 1500 0 0
								11000 4570 1300 1 0>;
				strategy_temp_normal_high =	<11000 4110 9100 0 120
								11000 4110 9000 0 120
								11000 4110 8500 0 180
								11000 4220 8100 0 180
								11000 4220 8000 0 180
								11000 4370 7700 0 180
								11000 4370 7500 0 180
								11000 4370 7000 0 0
								11000 4370 6500 0 0
								11000 4370 6000 0 0
								11000 4470 5900 0 0
								11000 4470 5500 0 0
								11000 4470 5000 0 0
								11000 4470 4500 0 0
								11000 4520 4400 0 0
								11000 4520 4000 0 0
								11000 4560 3500 0 0
								11000 4560 3000 0 0
								11000 4560 2500 0 0
								11000 4570 2200 1 0>;
				strategy_temp_warm =		<11000 4120 1700 0 0
								11000 4120 1500 0 0
								11000 4120 1000 0 0
								11000 4130 500 1 0>;
			};
			strategy_soc_range_mid_low {
				strategy_temp_little_cold =	<11000 4150 2200 0 0
								11000 4570 1160 1 0>;
				strategy_temp_cool =		<11000 4150 2400 0 0
								11000 4150 2000 0 0
								11000 4330 1500 0 0
								11000 4330 1000 0 0
								11000 4560 900 0 0
								11000 4570 500 1 0>;
				strategy_temp_little_cool =	<11000 4150 3000 0 0
								11000 4150 2500 0 0
								11000 4330 2400 0 0
								11000 4330 2000 0 0
								11000 4560 1500 0 0
								11000 4560 1000 0 0
								11000 4570 600 1 0>;
				strategy_temp_little_cool_high = <11000 4150 6100 0 0
								11000 4150 6000 0 0
								11000 4150 5500 0 0
								11000 4150 5000 0 0
								11000 4280 4500 0 0
								11000 4280 4000 0 0
								11000 4520 3600 0 0
								11000 4520 3500 0 0
								11000 4560 3000 0 0
								11000 4560 2500 0 0
								11000 4560 2000 0 0
								11000 4560 1500 0 0
								11000 4560 1000 0 0
								11000 4570 800 1 0>;
				strategy_temp_normal_low =	<11000 4110 9100 0 120
								11000 4110 9000 0 120
								11000 4110 8500 0 180
								11000 4220 8100 0 180
								11000 4220 8000 0 180
								11000 4370 7700 0 180
								11000 4370 7500 0 180
								11000 4370 7000 0 0
								11000 4370 6500 0 0
								11000 4370 6000 0 0
								11000 4470 5900 0 0
								11000 4470 5500 0 0
								11000 4470 5000 0 0
								11000 4470 4500 0 0
								11000 4520 4400 0 0
								11000 4520 4000 0 0
								11000 4560 3500 0 0
								11000 4560 3000 0 0
								11000 4560 2500 0 0
								11000 4560 2000 0 0
								11000 4560 1500 0 0
								11000 4570 1300 1 0>;
				strategy_temp_normal_high =	<11000 4110 9100 0 120
								11000 4110 9000 0 120
								11000 4110 8500 0 180
								11000 4220 8100 0 180
								11000 4220 8000 0 180
								11000 4370 7700 0 180
								11000 4370 7500 0 180
								11000 4370 7000 0 0
								11000 4370 6500 0 0
								11000 4370 6000 0 0
								11000 4470 5900 0 0
								11000 4470 5500 0 0
								11000 4470 5000 0 0
								11000 4470 4500 0 0
								11000 4520 4400 0 0
								11000 4520 4000 0 0
								11000 4560 3500 0 0
								11000 4560 3000 0 0
								11000 4560 2500 0 0
								11000 4570 2200 1 0>;
				strategy_temp_warm =		<11000 4120 1700 0 0
								11000 4120 1500 0 0
								11000 4120 1000 0 0
								11000 4130 500 1 0>;
			};
			strategy_soc_range_mid {
				strategy_temp_little_cold =	<11000 4150 2200 0 0
								11000 4570 1160 1 0>;
				strategy_temp_cool =		<11000 4150 2400 0 0
								11000 4150 2000 0 0
								11000 4330 1500 0 0
								11000 4330 1000 0 0
								11000 4560 900 0 0
								11000 4570 500 1 0>;
				strategy_temp_little_cool =	<11000 4150 3000 0 0
								11000 4150 2500 0 0
								11000 4330 2400 0 0
								11000 4330 2000 0 0
								11000 4560 1500 0 0
								11000 4560 1000 0 0
								11000 4570 600 1 0>;
				strategy_temp_little_cool_high = <11000 4280 4000 0 0
								11000 4520 3600 0 0
								11000 4520 3500 0 0
								11000 4560 3000 0 0
								11000 4560 2500 0 0
								11000 4560 2000 0 0
								11000 4560 1500 0 0
								11000 4560 1000 0 0
								11000 4570 800 1 0>;
				strategy_temp_normal_low =	<11000 4470 4500 0 0
								11000 4520 4400 0 0
								11000 4520 4000 0 0
								11000 4560 3500 0 0
								11000 4560 3000 0 0
								11000 4560 2500 0 0
								11000 4560 2000 0 0
								11000 4560 1500 0 0
								11000 4570 1300 1 0>;
				strategy_temp_normal_high =	<11000 4470 5000 0 0
								11000 4470 4500 0 0
								11000 4520 4400 0 0
								11000 4520 4000 0 0
								11000 4560 3500 0 0
								11000 4560 3000 0 0
								11000 4560 2500 0 0
								11000 4570 2200 1 0>;
				strategy_temp_warm =		<11000 4130 1000 1 0>;
			};
			strategy_soc_range_mid_high {
				strategy_temp_little_cold =	<11000 4150 2200 0 0
								11000 4570 1160 1 0>;
				strategy_temp_cool =		<11000 4150 2400 0 0
								11000 4150 2000 0 0
								11000 4330 1500 0 0
								11000 4330 1000 0 0
								11000 4560 900 0 0
								11000 4570 500 1 0>;
				strategy_temp_little_cool =	<11000 4150 3000 0 0
								11000 4150 2500 0 0
								11000 4330 2400 0 0
								11000 4330 2000 0 0
								11000 4560 1500 0 0
								11000 4560 1000 0 0
								11000 4570 600 1 0>;
				strategy_temp_little_cool_high = <11000 4560 3000 0 0
								11000 4560 2500 0 0
								11000 4560 2000 0 0
								11000 4560 1500 0 0
								11000 4560 1000 0 0
								11000 4570 800 1 0>;
				strategy_temp_normal_low =	<11000 4560 3500 0 0
								11000 4560 3000 0 0
								11000 4560 2500 0 0
								11000 4560 2000 0 0
								11000 4560 1500 0 0
								11000 4570 1300 1 0>;
				strategy_temp_normal_high =	<11000 4560 3500 0 0
								11000 4560 3000 0 0
								11000 4560 2500 0 0
								11000 4570 2200 1 0>;
				strategy_temp_warm =		<11000 4130 1000 1 0>;
			};
			strategy_soc_range_high {
				strategy_temp_little_cold =	<11000 4150 2200 0 0
								11000 4570 1160 1 0>;
				strategy_temp_cool =		<11000 4330 1500 0 0
								11000 4330 1000 0 0
								11000 4560 900 0 0
								11000 4570 500 1 0>;
				strategy_temp_little_cool =	<11000 4560 1500 0 0
								11000 4560 1000 0 0
								11000 4570 600 1 0>;
				strategy_temp_little_cool_high = <11000 4560 1500 0 0
								11000 4560 1000 0 0
								11000 4570 800 1 0>;
				strategy_temp_normal_low =	<11000 4560 2000 0 0
								11000 4560 1500 0 0
								11000 4570 1300 1 0>;
				strategy_temp_normal_high =	<11000 4570 2200 1 0>;
				strategy_temp_warm =		<11000 4130 1000 1 0>;
			};
		};

		oplus,impedance_node {
			ufcs_input_impedance: ufcs_input_impedance {
				node_name = "ufcs_mos";
				default_impedance_mohm = <0>;
				default_curr_ma = <9100>;
				current_drop_table = <
					125 10000
					130 8000
					190 5000
					250 4000
					340 3000
					380 2000
					480 0
				>;
			};
		};
	};

	oplus_ufcs_impedance_check: oplus,ufcs_impedance_check {
		compatible = "oplus,impedance_check";

		oplus,impedance_unit {
			oplus_ufcs_impedance_unit: oplus,ufcs_impedance_unit {
				uint_name = "ufcs";
				default_curr_ma = <9100>;
				impedance_node = <&ufcs_input_impedance>;
			};
		};
	};

	oplus_virtual_dpdm_switch: oplus,virtual_dpdm_switch {
		compatible = "oplus,virtual_dpdm_switch";

		oplus,ic_type = <OPLUS_CHG_IC_MISC>;
		oplus,ic_index = <0>;
		oplus,use_audio_switch;
	};

	oplus_chg_quirks: oplus,chg_quirks {
		compatible = "oplus,chg_quirks";
	};
	oplus_retention_charge: oplus,retention_charge {
		compatible = "oplus,retention_charge";
		oplus,topic-update-interval = <5000>;
		oplus,support_retention_name = "oplus_retention_quirks";
	};
};


&i2c1 {
	status = "ok";
	clock-frequency = <400000>;

	master_vphy_sc8517: sc8517-charger@69 {
		status = "okay";
		compatible = "sc,sc8517-master";
		reg = <0x69>;

		oplus,irq_gpio = <&pio 216 0x00>;
		oplus,v2x_volt_full_open_low;

		pinctrl-names = "charging_inter_active", "charging_inter_sleep";
		pinctrl-0 = <&charging_inter_active>;
		pinctrl-1 = <&charging_inter_sleep>;

		oplus,ic_type = <OPLUS_CHG_IC_VPHY>;
		oplus,ic_index = <0>;
		oplus,vooc-version = <VOOC_VERSION_5_0>;

		oplus_spec,external_gauge_support;
		oplus_spec,voocphy_bidirect_cp_support;
		oplus_spec,voocphy_current_default = <91>;
		oplus_spec,ap_control_allow;

		oplus_spec,svooc_cool_down_current_limit = <91 15 15 20 25 30 35 40 45 50 55 60 63 65 70 75 80 85 91>;
		oplus_spec,vooc_cool_down_current_limit = <61 20 20 20 30 40 50 60>;

		oplus_spec,vooc_little_cold_full_voltage = <4570>;
		oplus_spec,vooc_cool_full_voltage = <4570>;
		oplus_spec,vooc_little_cool_full_voltage = <4570>;
		oplus_spec,vooc_little_cool_high_full_voltage = <4570>;
		oplus_spec,vooc_warm_full_voltage = <4130>;
		oplus_spec,vooc_1time_full_voltage = <4585>;
		oplus_spec,vooc_ntime_full_voltage = <4575>;
		oplus_spec,full_voltage = < /* vol_1time vol_ntime */
			4580 4570 /* 0 ~ 5 */
			4580 4570 /* 5 ~ 12 */
			4580 4570 /* 12 ~ 16 */
			4580 4570 /* 16 ~ 20 */
			4585 4575 /* 20 ~ 35 */
			4580 4570 /* 35 ~ 44 */
			4140 4130 /* 44 ~ 51 */
		>;

		oplus_spec,low_curr_full_t1 = <120>;
		oplus_spec,low_curr_full_t2 = <350>;
		oplus_spec,low_curr_full_t3 = <430>;
		oplus_spec,range1_low_curr_full = <1350 4540
						1250 4535
						1150 4520
						1050 4510
						950 4500>;
		oplus_spec,range2_low_curr_full = <1450 4540
						1350 4535
						1250 4520
						1150 4510
						1050 4500>;

		oplus_spec,vooc_multistep_initial_batt_temp = <1000>;
		oplus_spec,vooc_little_cool_temp = <160>;
		oplus_spec,vooc_little_cool_high_temp = <210>;
		oplus_spec,vooc_cool_temp = <120>;
		oplus_spec,vooc_little_cold_temp = <50>;
		oplus_spec,vooc_normal_low_temp = <350>;
		oplus_spec,vooc_strategy_normal_current = <100>;
		oplus_spec,vooc_normal_to_little_cool_current = <100>;
		oplus_spec,vooc_over_high_temp = <510>;
		oplus_spec,vooc_low_temp = <50>;
		oplus_spec,vooc_high_temp = <500>;
		oplus_spec,vooc_low_soc = <0>;
		oplus_spec,vooc_high_soc = <90>;
		oplus_spec,vooc_normal_high_temp = <440>;
		oplus_spec,vooc_warm_vol_thr = <4000>;
		oplus_spec,vooc_warm_soc_thr = <55>;
		oplus_spec,impedance_calculation_newmethod;
		oplus_spec,svooc_circuit_r_l = <0x18>;
		oplus_spec,svooc_circuit_r_h = <0x2>;/* 65 mR */

		oplus_spec,fastchg_timeout_time_init = <165850>;
		oplus_spec,voocphy_ibat_over_current = <10500>;
		oplus_spec,voocphy_cp_max_ibus = <10500>;
		oplus_spec,voocphy_svooc_cp_max_ibus = <3500>;
		oplus_spec,voocphy_vooc_cp_max_ibus = <3500>;
		oplus_spec,batt_pwd_curr_thd1 = <3800>;
		oplus_spec,batt_pwd_vol_thd1 = <4605>;

		oplus_spec,voocphy_freq_mincore = <940800>;
		oplus_spec,voocphy_freq_midcore = <1440000>;
		oplus_spec,voocphy_freq_maxcore = <1538000>;
		oplus_spec,voocphy_current_change_timeout = <100>;
		oplus_spec,copycat_vooc_support;

		oplus,abnormal_adapter_current = <CURR_LIMIT_7BIT_9_5A CURR_LIMIT_7BIT_9_5A
						  CURR_LIMIT_7BIT_5_0A CURR_LIMIT_7BIT_5_0A
						  CURR_LIMIT_7BIT_4_0A CURR_LIMIT_7BIT_4_0A
						  CURR_LIMIT_7BIT_3_0A CURR_LIMIT_7BIT_3_0A
						  CURR_LIMIT_7BIT_2_0A CURR_LIMIT_7BIT_2_0A>;

		oplus_spec,soc_range = <0 20 35 55 75 85 90>;

		svooc_batt_sys_curve = <1 0 1 1 0 1 1	// 9100mA
					1 0 1 1 1 0 0	// 4324mV
					0 0 1 0 1 0 0	// 2000mA
					1 1 1 0 1 1 1	// 4594mV
					0 0 0 1 1 0 0	// 1200mA
					1 1 1 0 1 1 1>; // 4594mV

		vooc_batt_sys_curve =  <0 1 0 1 1 0 1 	// 4500mA
					0 0 0 0 0 0 1	// 3414mV
					0 0 1 0 1 0 0	// 2000mA
					1 1 1 0 1 1 1	// 4594mV
					0 0 0 1 0 1 0	// 1000mA
					1 1 1 0 1 1 1>; // 4594mV

		svooc_lcf_strategy {
			oplus,temp_type = <OPLUS_STRATEGY_USE_SHELL_TEMP>;
			oplus,temp_range = <0 50 120 160 210 380 440>;

			strategy_temp_range_curves {
				strategy_temp_range_t0 =	<460 4570 0
								 435 4560 0
								 410 4550 0
								 385 4540 0
								 360 4530 1>;
				strategy_temp_range_t1 =	<500 4570 0
								 465 4565 0
								 430 4550 0
								 395 4540 0
								 360 4530 1>;
				strategy_temp_range_t2 =	<600 4570 0
								 555 4565 0
								 510 4550 0
								 465 4540 0
								 420 4530 1>;
				strategy_temp_range_t3 =	<750 4570 0
								 700 4565 0
								 600 4550 0
								 550 4540 0
								 350 4530 1>;
				strategy_temp_range_t4 =	<1250 4570 0
								 1200 4565 0
								 1100 4550 0
								 1000 4540 0
								 850 4530 1>;
				strategy_temp_range_t5 =	<2150 4570 0
								 2100 4565 0
								 2000 4550 0
								 1900 4540 0
								 1750 4530 1>;
			};
		};

		svooc_charge_strategy {
			strategy_soc_0_to_50 { /* 0 ~ 20 */
				strategy_temp_little_cold =	<4150 22 0 0 0
								4570  11 1 0 0>;
				strategy_temp_cool =		<4150 24 0 0 0
								4150 20 0 0 0
								4330 15 0 0 0
								4330 10 0 0 0
								4560 9  0 0 0
								4570 5  0 0 0>;
				strategy_temp_little_cool =	<4150 30 0 0 0
								4150 25 0 0 0
								4330 24 0 0 0
								4330 20 0 0 0
								4560 15 0 0 0
								4560 10 0 0 0
								4570  6 1 0 0>;
				strategy_temp_little_cool_high =	<4150 61 0 0 0
								4150 60 0 0 0
								4150 55 0 0 0
								4150 50 0 0 0
								4280 45 0 0 0
								4280 40 0 0 0
								4520 36 0 0 0
								4520 35 0 0 0
								4560 30 0 0 0
								4560 25 0 0 0
								4560 20 0 0 0
								4560 15 0 0 0
								4560 10 0 0 0
								4570  8 1 0 0>;
				strategy_temp_normal_low =	<4110 91 0 240 0
								4110 90 0 240 0
								4110 85 0 360 0
								4220 81 0 360 0
								4220 80 0 360 0
								4370 77 0 360 0
								4370 75 0 360 0
								4370 70 0 0 0
								4370 65 0 0 0
								4370 60 0 0 0
								4470 59 0 0 0
								4470 55 0 0 0
								4470 50 0 0 0
								4470 45 0 0 0
								4520 44 0 0 0
								4520 40 0 0 0
								4560 35 0 0 0
								4560 30 0 0 0
								4560 25 0 0 0
								4560 20 0 0 0
								4560 15 0 0 0
								4570 13 1 0 0>;
				strategy_temp_normal_high =	<4110 91 0 240 0
								4110 90 0 240 0
								4110 85 0 360 0
								4220 81 0 360 0
								4220 80 0 360 0
								4370 77 0 360 0
								4370 75 0 360 0
								4370 70 0 0 0
								4370 65 0 0 0
								4370 60 0 0 0
								4470 59 0 0 0
								4470 55 0 0 0
								4470 50 0 0 0
								4470 45 0 0 0
								4520 44 0 0 0
								4520 40 0 0 0
								4560 35 0 0 0
								4560 30 0 0 0
								4560 25 0 0 0
								4570 22 1 0 0>;
				strategy_temp_warm =		<4120 17 0 0 0
								4120 15 0 0 0
								4120 10 0 0 0
								4130  5 1 0 0>;
			};

			strategy_soc_0_to_50_mid { /* 21 ~ 35 */
				strategy_temp_little_cold =	<4150 22 0 0 0
								4570  11 1 0 0>;
				strategy_temp_cool = <4150 24 0 0 0
								4150 20 0 0 0
								4330 15 0 0 0
								4330 10 0 0 0
								4560 9 0 0 0
								4570 5 1 0 0>;
				strategy_temp_little_cool =	<4150 30 0 0 0
								4150 25 0 0 0
								4330 24 0 0 0
								4330 20 0 0 0
								4560 15 0 0 0
								4560 10 0 0 0
								4570  6 1 0 0>;
				strategy_temp_little_cool_high = <4150 61 0 0 0
								4150 60 0 0 0
								4150 55 0 0 0
								4150 50 0 0 0
								4280 45 0 0 0
								4280 40 0 0 0
								4520 36 0 0 0
								4520 35 0 0 0
								4560 30 0 0 0
								4560 25 0 0 0
								4560 20 0 0 0
								4560 15 0 0 0
								4560 10 0 0 0
								4570  8 1 0 0>;
				strategy_temp_normal_low =	<4110 91 0 240 0
								4110 90 0 240 0
								4110 85 0 360 0
								4220 81 0 360 0
								4220 80 0 360 0
								4370 77 0 360 0
								4370 75 0 360 0
								4370 70 0 0 0
								4370 65 0 0 0
								4370 60 0 0 0
								4470 59 0 0 0
								4470 55 0 0 0
								4470 50 0 0 0
								4470 45 0 0 0
								4520 44 0 0 0
								4520 40 0 0 0
								4560 35 0 0 0
								4560 30 0 0 0
								4560 25 0 0 0
								4560 20 0 0 0
								4560 15 0 0 0
								4570 13 1 0 0>;
				strategy_temp_normal_high =	<4110 91 0 240 0
								4110 90 0 240 0
								4110 85 0 360 0
								4220 81 0 360 0
								4220 80 0 360 0
								4370 77 0 360 0
								4370 75 0 360 0
								4370 70 0 0 0
								4370 65 0 0 0
								4370 60 0 0 0
								4470 59 0 0 0
								4470 55 0 0 0
								4470 50 0 0 0
								4470 45 0 0 0
								4520 44 0 0 0
								4520 40 0 0 0
								4560 35 0 0 0
								4560 30 0 0 0
								4560 25 0 0 0
								4570 22 1 0 0>;
				strategy_temp_warm =		<4120 17 0 0 0
								4120 15 0 0 0
								4120 10 0 0 0
								4130  5 1 0 0>;
			};

			strategy_soc_0_to_50_high { /* 36 ~ 55 */
				strategy_temp_little_cold =	<4150 22 0 0 0
								4570  11 1 0 0>;
				strategy_temp_cool =		<4150 24 0 0 0
								4150 20 0 0 0
								4330 15 0 0 0
								4330 10 0 0 0
								4560  9 0 0 0
								4570  5 1 0 0>;
				strategy_temp_little_cool =	<4150 30 0 0 0
								4150 25 0 0 0
								4330 24 0 0 0
								4330 20 0 0 0
								4560 15 0 0 0
								4560 10 0 0 0
								4570  6 1 0 0>;
				strategy_temp_little_cool_high =	<4150 61 0 0 0
								4150 60 0 0 0
								4150 55 0 0 0
								4150 50 0 0 0
								4280 45 0 0 0
								4280 40 0 0 0
								4520 36 0 0 0
								4520 35 0 0 0
								4560 30 0 0 0
								4560 25 0 0 0
								4560 20 0 0 0
								4560 15 0 0 0
								4560 10 0 0 0
								4570  8 1 0 0>;
				strategy_temp_normal_low =	<4110 91 0 240 0
								4110 90 0 240 0
								4110 85 0 360 0
								4220 81 0 360 0
								4220 80 0 360 0
								4370 77 0 360 0
								4370 75 0 360 0
								4370 70 0 0 0
								4370 65 0 0 0
								4370 60 0 0 0
								4470 59 0 0 0
								4470 55 0 0 0
								4470 50 0 0 0
								4470 45 0 0 0
								4520 44 0 0 0
								4520 40 0 0 0
								4560 35 0 0 0
								4560 30 0 0 0
								4560 25 0 0 0
								4560 20 0 0 0
								4560 15 0 0 0
								4570 13 1 0 0>;
				strategy_temp_normal_high =	<4110 91 0 240 0
								4110 90 0 240 0
								4110 85 0 360 0
								4220 81 0 360 0
								4220 80 0 360 0
								4370 77 0 360 0
								4370 75 0 360 0
								4370 70 0 0 0
								4370 65 0 0 0
								4370 60 0 0 0
								4470 59 0 0 0
								4470 55 0 0 0
								4470 50 0 0 0
								4470 45 0 0 0
								4520 44 0 0 0
								4520 40 0 0 0
								4560 35 0 0 0
								4560 30 0 0 0
								4560 25 0 0 0
								4570 22 1 0 0>;
				strategy_temp_warm =		<4120 17 0 0 0
								4120 15 0 0 0
								4120 10 0 0 0
								4130  5 1 0 0>;
			};

			strategy_soc_50_to_75 { /* 56 ~ 75 */
				strategy_temp_little_cold =	<4150 22 0 0 0
								4570  11 1 0 0>;
				strategy_temp_cool =		<4150 24 0 0 0
								4150 20 0 0 0
								4330 15 0 0 0
								4330 10 0 0 0
								4560  9 0 0 0
								4570  5 1 0 0>;
				strategy_temp_little_cool =	<4150 30 0 0 0
								4150 25 0 0 0
								4330 24 0 0 0
								4330 20 0 0 0
								4560 15 0 0 0
								4560 10 0 0 0
								4570  6 1 0 0>;
				strategy_temp_little_cool_high =	<4280 40 0 0 0
								4520 36 0 0 0
								4520 35 0 0 0
								4560 30 0 0 0
								4560 25 0 0 0
								4560 20 0 0 0
								4560 15 0 0 0
								4560 10 0 0 0
								4570  8 1 0 0>;
				strategy_temp_normal_low =	<4470 45 0 0 0
								4520 44 0 0 0
								4520 40 0 0 0
								4560 35 0 0 0
								4560 30 0 0 0
								4560 25 0 0 0
								4560 20 0 0 0
								4560 15 0 0 0
								4570 13 1 0 0>;
				strategy_temp_normal_high =	<4470 50 0 0 0
								4470 45 0 0 0
								4520 44 0 0 0
								4520 40 0 0 0
								4560 35 0 0 0
								4560 30 0 0 0
								4560 25 0 0 0
								4570 22 1 0 0>;
			};

			strategy_soc_75_to_85 { /* 76 ~ 85 */
				strategy_temp_little_cold =	<4150 22 0 0 0
								4570  11 1 0 0>;
				strategy_temp_cool =		<4150 24 0 0 0
								4150 20 0 0 0
								4330 15 0 0 0
								4330 10 0 0 0
								4560  9 0 0 0
								4570  5 1 0 0>;
				strategy_temp_little_cool =	<4150 30 0 0 0
								4150 25 0 0 0
								4330 24 0 0 0
								4330 20 0 0 0
								4560 15 0 0 0
								4560 10 0 0 0
								4570  6 1 0 0>;
				strategy_temp_little_cool_high =	<4560 30 0 0 0
								4560 25 0 0 0
								4560 20 0 0 0
								4560 15 0 0 0
								4560 10 0 0 0
								4570  8 1 0 0>;
				strategy_temp_normal_low =	<4560 35 0 0 0
								4560 30 0 0 0
								4560 25 0 0 0
								4560 20 0 0 0
								4560 15 0 0 0
								4570 13 1 0 0>;
				strategy_temp_normal_high =	<4560 35 0 0 0
								4560 30 0 0 0
								4560 25 0 0 0
								4570 22 1 0 0>;
			};

			strategy_soc_85_to_90 { /* 86 ~ 90 */
				strategy_temp_little_cold =	<4150 22 0 0 0
								4570  11 1 0 0>;
				strategy_temp_cool =		<4330 15 0 0 0
								4330 10 0 0 0
								4560  9 0 0 0
								4570  5 1 0 0>;
				strategy_temp_little_cool =	<4560 15 0 0 0
								4560 10 0 0 0
								4570  6 1 0 0>;
				strategy_temp_little_cool_high =	<4560 15 0 0 0
								4560 10 0 0 0
								4570  8 1 0 0>;
				strategy_temp_normal_low =	<4560 20 0 0 0
								4560 15 0 0 0
								4570 13 1 0 0>;
				strategy_temp_normal_high =	<4570 22 1 0 0>;
			};
		};

		vooc_charge_strategy {
			strategy_soc_0_to_50 {
				strategy_temp_little_cold =	<4430 20 1 0 0>;
				strategy_temp_cool =		<4420 30 0 0 0
								 4430 20 1 0 0>;
				strategy_temp_little_cool =	<4475 30 0 0 0
								 4480 20 1 0 0>;
				strategy_temp_little_cool_high =	<4475 30 0 0 0
								 4480 20 1 0 0>;
				strategy_temp_normal_low =	<4475 30 0 0 0
								 4480 20 1 0 0>;
				strategy_temp_normal_high =	<4475 30 0 0 0
								 4480 20 1 0 0>;
				strategy_temp_warm =		<4130 24 1 0 0>;
			};

			strategy_soc_0_to_50_mid {
				strategy_temp_little_cold =	<4430 20 1 0 0>;
				strategy_temp_cool =		<4420 30 0 0 0
								 4430 20 1 0 0>;
				strategy_temp_little_cool =	<4475 30 0 0 0
								 4480 20 1 0 0>;
				strategy_temp_little_cool_high =	<4475 30 0 0 0
								 4480 20 1 0 0>;
				strategy_temp_normal_low =	<4475 30 0 0 0
								 4480 20 1 0 0>;
				strategy_temp_normal_high =	<4475 30 0 0 0
								 4480 20 1 0 0>;
				strategy_temp_warm =		<4130 24 1 0 0>;
			};

			strategy_soc_0_to_50_high {
				strategy_temp_little_cold =	<4430 20 1 0 0>;
				strategy_temp_cool =		<4420 30 0 0 0
								 4430 20 1 0 0>;
				strategy_temp_little_cool =	<4475 30 0 0 0
								 4480 20 1 0 0>;
				strategy_temp_little_cool_high =	<4475 30 0 0 0
								 4480 20 1 0 0>;
				strategy_temp_normal_low =	<4475 30 0 0 0
								 4480 20 1 0 0>;
				strategy_temp_normal_high =	<4475 30 0 0 0
								 4480 20 1 0 0>;
				strategy_temp_warm =		<4130 24 1 0 0>;
			};

			strategy_soc_50_to_75 {
				strategy_temp_little_cold =	<4430 20 1 0 0>;
				strategy_temp_cool =		<4420 30 0 0 0
								 4430 20 1 0 0>;
				strategy_temp_little_cool =	<4475 30 0 0 0
								 4480 20 1 0 0>;
				strategy_temp_little_cool_high =	<4475 30 0 0 0
								 4480 20 1 0 0>;
				strategy_temp_normal_low =	<4475 30 0 0 0
								 4480 20 1 0 0>;
				strategy_temp_normal_high =	<4475 30 0 0 0
								 4480 20 1 0 0>;
				strategy_temp_warm =		<4130 24 1 0 0>;
			};

			strategy_soc_75_to_85 {
				strategy_temp_little_cold =	<4430 20 1 0 0>;
				strategy_temp_cool =		<4430 20 1 0 0>;
				strategy_temp_little_cool =	<4480 20 1 0 0>;
				strategy_temp_little_cool_high =	<4480 20 1 0 0>;
				strategy_temp_normal_low =	<4475 30 0 0 0
								 4480 20 1 0 0>;
				strategy_temp_normal_high =	<4475 30 0 0 0
								 4480 20 1 0 0>;
				strategy_temp_warm =		<4130 24 1 0 0>;
			};

			strategy_soc_85_to_90 {
				strategy_temp_little_cold =	<4430 20 1 0 0>;
				strategy_temp_cool =		<4430 20 1 0 0>;
				strategy_temp_little_cool =	<4480 20 1 0 0>;
				strategy_temp_little_cool_high =	<4480 20 1 0 0>;
				strategy_temp_normal_low =	<4480 20 1 0 0>;
				strategy_temp_normal_high =	<4480 20 1 0 0>;
				strategy_temp_warm =		<4130 24 1 0 0>;
			};
		};

		oplus_sc8517_cp: oplus,sc8517_cp {
			oplus,ic_type = <OPLUS_CHG_IC_CP>;
			oplus,ic_index = <0>;
		};
	};
};

&i2c1 {
	pinctrl-names = "i2c-state", "output-low-state";
	pinctrl-0 = <&i2c1_i2c_state>;
	pinctrl-1 = <&i2c1_output_low_state>;
};

&pio {
	i2c1_i2c_state: i2c1_sda_i2c_state {
		pins_cmd_dat {
			pinmux = <PINMUX_GPIO200__FUNC_SCL1>,
			<PINMUX_GPIO201__FUNC_SDA1>;
			bias-disable;
		};
	};
	i2c1_output_low_state: i2c1_sda_output_low_state {
		pins_cmd_dat {
			pinmux = <PINMUX_GPIO200__FUNC_GPIO200>,
			<PINMUX_GPIO201__FUNC_GPIO201>;
			output-low;
		};
	};
};

&i2c6 {
	status = "okay";
	clock-frequency = <400000>;

	byb_tps6128xd: byb-tps6128xd@75 {
		status = "okay";
		compatible = "oplus,byb-tps6128xd";
		reg = <0x75>;
		oplus,ic_type = <OPLUS_CHG_IC_BOOST>;
		oplus,ic_index = <0>;
		oplus,vout-mv = <3350>;
		oplus,ilim-ma = <4500>;
	};
};

&i2c13 {
	status = "okay";
	clock-frequency = <400000>;

	byb_tps6128xd_second: byb-tps6128xd@75 {
		status = "okay";
		compatible = "oplus,byb-tps6128xd";
		reg = <0x75>;
		oplus,ic_type = <OPLUS_CHG_IC_BOOST>;
		oplus,ic_index = <1>;
		oplus,vout-mv = <3350>;
		oplus,ilim-ma = <4500>;
	};
};
/* chagrge end */


&i2c3 {
	status = "okay";
	clock-frequency = <400000>;

	oplus_sc2201: sc8517-sc2201@72{
		status = "okay";
		compatible = "oplus,sc2201-ufcs";
		reg = <0x72>;

		oplus,ufcs_int-gpio = <&pio 38 0>;
		oplus,ufcs_en-gpio = <&pio 193 0>;

		pinctrl-names = "ufcs_int_default", "ufcs_en_active", "ufcs_en_sleep";
		pinctrl-0 = <&ufcs_int_default>;
		pinctrl-1 = <&ufcs_en_active>;
		pinctrl-2 = <&ufcs_en_sleep>;
	};
};

&pio {
	ufcs_int_default: ufcs_int_default {
		pins_cmd_dat {
			pinmux = <PINMUX_GPIO38__FUNC_GPIO38>;
			input-enable;
			bias-pull-up;
		};
	};
	ufcs_en_active: ufcs_en_active {
		pins_cmd_dat {
			pinmux = <PINMUX_GPIO193__FUNC_GPIO193>;
			bias-pull-up;
			input-disable;
			output-high;
		};
	};
	ufcs_en_sleep: ufcs_en_sleep {
		pins_cmd_dat {
			pinmux = <PINMUX_GPIO193__FUNC_GPIO193>;
			bias-pull-down;
			input-disable;
			output-low;
		};
	};
};

&soc {
	oplus_chg_plc: oplus,plc_charge {
		compatible = "oplus,plc_charge";
		oplus,plc_soc = <90>;
		oplus,plc_support_timeout;
		oplus,plc_strategy-data = <&buck_simple_strategy>;
		oplus,plc_strategy-names = "default";

		oplus_ufcs_step_strategy: oplus_ufcs_step_strategy {
			oplus,strategy_type = <PLC_STRATEGY_STEP>;
		};

		third_ufcs_simple_strategy: third_ufcs_simple_strategy {
			oplus,strategy_type = <PLC_STRATEGY_SIMPLE>;
			oplus,strategy_data {
				strategy_curr_ma = <1000 1500>;
			};
		};

		pps_simple_strategy: pps_simple_strategy {
			oplus,strategy_type = <PLC_STRATEGY_SIMPLE>;
			oplus,strategy_data {
				strategy_curr_ma = <1000 1500>;
			};
		};

		svooc_simple_strategy: svooc_simple_strategy {
			oplus,strategy_type = <PLC_STRATEGY_SIMPLE>;
			oplus,strategy_data {
				strategy_curr_ma = <1000 1500>;
			};
		};

		vooc_simple_strategy: vooc_simple_strategy {
			oplus,strategy_type = <PLC_STRATEGY_SIMPLE>;
			oplus,strategy_data {
				strategy_curr_ma = <2000 3000>;
			};
		};

		buck_simple_strategy: buck_simple_strategy {
			oplus,strategy_type = <PLC_STRATEGY_SIMPLE>;
		};
	};
};

//#endif OPLUS_FEATURE_CHG_BASIC
